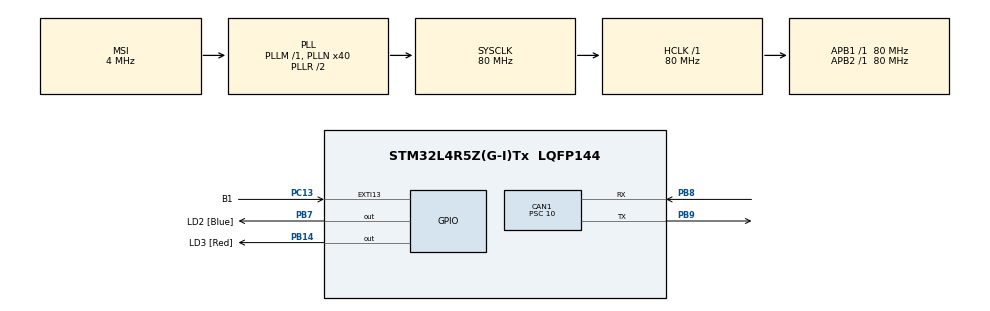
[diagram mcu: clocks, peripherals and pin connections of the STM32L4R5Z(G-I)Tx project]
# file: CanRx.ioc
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CAN1.BS1=CAN_BS1_13TQ
CAN1.BS2=CAN_BS2_2TQ
CAN1.CalculateBaudRate=500000
CAN1.CalculateTimeBit=2000.00
CAN1.CalculateTimeQuantum=125.0
CAN1.Prescaler=10
Mcu.Family=STM32L4
Mcu.Name=STM32L4R5Z(G-I)Tx
Mcu.Package=LQFP144
NVIC.CAN1_RX1_IRQn=true\:0\:0\:false\:false\:true\:true\:true
NVIC.PriorityGroup=NVIC_PRIORITYGROUP_4
PB14.GPIO_Label=LD3 [Red]
PB14.Signal=GPIO_Output
PB7.GPIO_Label=LD2 [Blue]
PB7.Signal=GPIO_Output
PB8.Mode=CAN_Activate
PB8.Signal=CAN1_RX
PB9.Mode=CAN_Activate
PB9.Signal=CAN1_TX
PC13.GPIO_Label=B1
PC13.Signal=GPXTI13
PC14-OSC32_IN\ (PC14).Mode=LSE-External-Oscillator
PC14-OSC32_IN\ (PC14).Signal=RCC_OSC32_IN
PC15-OSC32_OUT\ (PC15).Mode=LSE-External-Oscillator
PC15-OSC32_OUT\ (PC15).Signal=RCC_OSC32_OUT
ProjectManager.HeapSize=0x200
ProjectManager.StackSize=0x400
ProjectManager.TargetToolchain=SW4STM32
RCC.48MHZClocksFreq_Value=24000000
RCC.AHBFreq_Value=80000000
RCC.APB1Freq_Value=80000000
RCC.APB1TimFreq_Value=80000000
RCC.APB2Freq_Value=80000000
RCC.APB2TimFreq_Value=80000000
RCC.CortexFreq_Value=80000000
RCC.HCLKFreq_Value=80000000
RCC.HSE_VALUE=8000000
RCC.HSI48_VALUE=48000000
RCC.HSI_VALUE=16000000
RCC.MSI_VALUE=4000000
RCC.PLLMUL=RCC_PLL_MUL9
RCC.PLLN=40
RCC.PRESCALERUSB=RCC_USBCLKSOURCE_PLL_DIV1_5
RCC.SYSCLKFreq_VALUE=80000000
RCC.SYSCLKSource=RCC_SYSCLKSOURCE_PLLCLK
RCC.SYSCLKSourceVirtual=RCC_SYSCLKSOURCE_PLLCLK
RCC.USBFreq_Value=16000000
RCC.VCOOutputFreq_Value=160000000
board=NUCLEO-L4R5ZI

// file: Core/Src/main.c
/* USER CODE BEGIN Header */
/**
  ******************************************************************************
  * @file           : main.c
  * @brief          : Main program body
  ******************************************************************************
  * @attention
  *
  * <h2><center>&copy; Copyright (c) 2021 STMicroelectronics.
  * All rights reserved.</center></h2>
  *
  * This software component is licensed by ST under BSD 3-Clause license,
  * the "License"; You may not use this file except in compliance with the
  * License. You may obtain a copy of the License at:
  *                        opensource.org/licenses/BSD-3-Clause
  *
  ******************************************************************************
  */
/* USER CODE END Header */
#include "main.h"

/* USER CODE BEGIN Includes */
#include "CanRx.h"
/* USER CODE END Includes */

CAN_HandleTypeDef hcan1;

void SystemClock_Config(void);
static void MX_GPIO_Init(void);
static void MX_CAN1_Init(void);

int main(void)
{

  /* MCU Configuration--------------------------------------------------------*/

  /* Reset of all peripherals, Initializes the Flash interface and the Systick. */
  HAL_Init();

  /* Configure the system clock */
  SystemClock_Config();

  /* Initialize all configured peripherals */
  MX_GPIO_Init();
  MX_CAN1_Init();
  /* USER CODE BEGIN 2 */
  Boot();
  /* USER CODE END 2 */

  /* Infinite loop */
  while (1)
  {

  }
}

void SystemClock_Config(void)
{
  RCC_OscInitTypeDef RCC_OscInitStruct = {0};
  RCC_ClkInitTypeDef RCC_ClkInitStruct = {0};

  /** Configure the main internal regulator output voltage
  */
  if (HAL_PWREx_ControlVoltageScaling(PWR_REGULATOR_VOLTAGE_SCALE1) != HAL_OK)
  {
    Error_Handler();
  }
  /** Initializes the RCC Oscillators according to the specified parameters
  * in the RCC_OscInitTypeDef structure.
  */
  RCC_OscInitStruct.OscillatorType = RCC_OSCILLATORTYPE_MSI;
  RCC_OscInitStruct.MSIState = RCC_MSI_ON;
  RCC_OscInitStruct.MSICalibrationValue = 0;
  RCC_OscInitStruct.MSIClockRange = RCC_MSIRANGE_6;
  RCC_OscInitStruct.PLL.PLLState = RCC_PLL_ON;
  RCC_OscInitStruct.PLL.PLLSource = RCC_PLLSOURCE_MSI;
  RCC_OscInitStruct.PLL.PLLM = 1;
  RCC_OscInitStruct.PLL.PLLN = 40;
  RCC_OscInitStruct.PLL.PLLP = RCC_PLLP_DIV2;
  RCC_OscInitStruct.PLL.PLLQ = RCC_PLLQ_DIV2;
  RCC_OscInitStruct.PLL.PLLR = RCC_PLLR_DIV2;
  if (HAL_RCC_OscConfig(&RCC_OscInitStruct) != HAL_OK)
  {
    Error_Handler();
  }
  /** Initializes the CPU, AHB and APB buses clocks
  */
  RCC_ClkInitStruct.ClockType = RCC_CLOCKTYPE_HCLK|RCC_CLOCKTYPE_SYSCLK
                              |RCC_CLOCKTYPE_PCLK1|RCC_CLOCKTYPE_PCLK2;
  RCC_ClkInitStruct.SYSCLKSource = RCC_SYSCLKSOURCE_PLLCLK;
  RCC_ClkInitStruct.AHBCLKDivider = RCC_SYSCLK_DIV1;
  RCC_ClkInitStruct.APB1CLKDivider = RCC_HCLK_DIV1;
  RCC_ClkInitStruct.APB2CLKDivider = RCC_HCLK_DIV1;

  if (HAL_RCC_ClockConfig(&RCC_ClkInitStruct, FLASH_LATENCY_3) != HAL_OK)
  {
    Error_Handler();
  }
}

static void MX_CAN1_Init(void)
{

  hcan1.Instance = CAN1;
  hcan1.Init.Prescaler = 10;
  hcan1.Init.Mode = CAN_MODE_NORMAL;
  hcan1.Init.SyncJumpWidth = CAN_SJW_1TQ;
  hcan1.Init.TimeSeg1 = CAN_BS1_13TQ;
  hcan1.Init.TimeSeg2 = CAN_BS2_2TQ;
  hcan1.Init.TimeTriggeredMode = DISABLE;
  hcan1.Init.AutoBusOff = DISABLE;
  hcan1.Init.AutoWakeUp = DISABLE;
  hcan1.Init.AutoRetransmission = DISABLE;
  hcan1.Init.ReceiveFifoLocked = DISABLE;
  hcan1.Init.TransmitFifoPriority = DISABLE;
  if (HAL_CAN_Init(&hcan1) != HAL_OK)
  {
    Error_Handler();
  }

}

static void MX_GPIO_Init(void)
{
  GPIO_InitTypeDef GPIO_InitStruct = {0};

  /* GPIO Ports Clock Enable */
  __HAL_RCC_GPIOC_CLK_ENABLE();
  __HAL_RCC_GPIOB_CLK_ENABLE();

  /*Configure GPIO pin Output Level */
  HAL_GPIO_WritePin(GPIOB, LD3_Pin|LD2_Pin, GPIO_PIN_RESET);

  /*Configure GPIO pin : B1_Pin */
  GPIO_InitStruct.Pin = B1_Pin;
  GPIO_InitStruct.Mode = GPIO_MODE_IT_RISING;
  GPIO_InitStruct.Pull = GPIO_NOPULL;
  HAL_GPIO_Init(B1_GPIO_Port, &GPIO_InitStruct);

  /*Configure GPIO pins : LD3_Pin LD2_Pin */
  GPIO_InitStruct.Pin = LD3_Pin|LD2_Pin;
  GPIO_InitStruct.Mode = GPIO_MODE_OUTPUT_PP;
  GPIO_InitStruct.Pull = GPIO_NOPULL;
  GPIO_InitStruct.Speed = GPIO_SPEED_FREQ_LOW;
  HAL_GPIO_Init(GPIOB, &GPIO_InitStruct);

}

void Error_Handler(void)
{
  __disable_irq();
  while (1)
  {
  }
}

/************************ (C) COPYRIGHT STMicroelectronics *****END OF FILE****/
